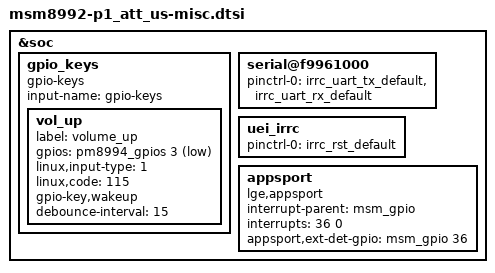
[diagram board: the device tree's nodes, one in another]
/* Copyright (c) 2014, The Linux Foundation. All rights reserved.
 *
 * This program is free software; you can redistribute it and/or modify
 * it under the terms of the GNU General Public License version 2 and
 * only version 2 as published by the Free Software Foundation.
 *
 * This program is distributed in the hope that it will be useful,
 * but WITHOUT ANY WARRANTY; without even the implied warranty of
 * MERCHANTABILITY or FITNESS FOR A PARTICULAR PURPOSE.  See the
 * GNU General Public License for more details.
 */

#include "../pmi8994-haptic.dtsi"

&soc {
    gpio_keys {
        compatible = "gpio-keys";
        input-name = "gpio-keys";

        vol_up {
            label = "volume_up";
            gpios = <&pm8994_gpios 3 0x1>;
            linux,input-type = <1>;
            linux,code = <115>;
            gpio-key,wakeup;
            debounce-interval = <15>;
        };
    };

	serial@f9961000 {
		status = "ok";
		pinctrl-names = "default";
		pinctrl-0 = <&irrc_uart_tx_default &irrc_uart_rx_default>;
	};

	uei_irrc {
		status = "ok";
		pinctrl-names = "default";
		pinctrl-0 = <&irrc_rst_default>;
	};

	appsport {
		status = "okay";
		compatible = "lge,appsport";
		interrupt-parent = <&msm_gpio>;
		interrupts = <36 0>;
		interrupt-names = "ext_det_irq";
		appsport,ext-det-gpio = <&msm_gpio 36 0>;
	};
};

